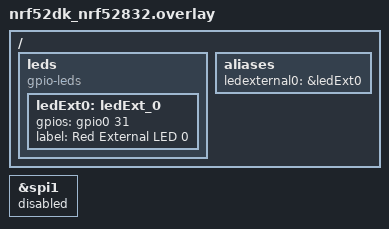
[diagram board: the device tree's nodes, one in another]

/{
   leds{
    compatible = "gpio-leds";
    ledExt0: ledExt_0 {
        gpios = <&gpio0 31 GPIO_ACTIVE_HIGH>;
        label = "Red External LED 0";
    };
   }; 
   aliases{
    ledexternal0 = &ledExt0;
   };
};

&spi1 {
    status = "disabled";
};


